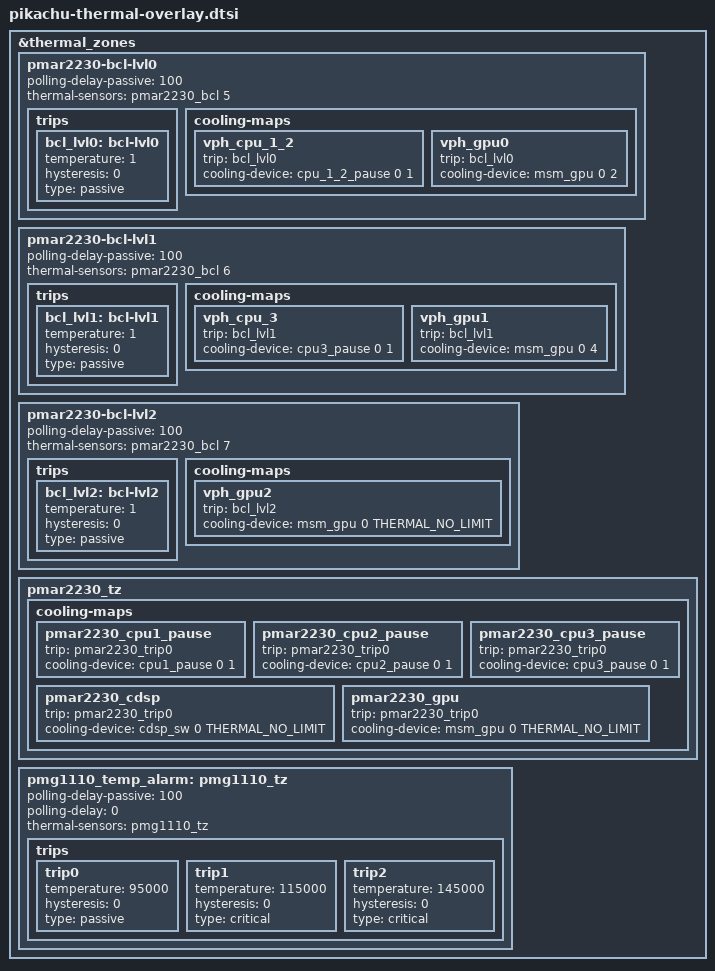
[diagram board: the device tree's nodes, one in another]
// SPDX-License-Identifier: BSD-3-Clause
/*
 * Copyright (c) Qualcomm Technologies, Inc. and/or its subsidiaries.
 */

#include <dt-bindings/thermal/thermal_qti.h>

&thermal_zones {
	pmar2230-bcl-lvl0 {
		polling-delay-passive = <100>;
		thermal-sensors = <&pmar2230_bcl 5>;

		trips {
			bcl_lvl0: bcl-lvl0 {
				temperature = <1>;
				hysteresis = <0>;
				type = "passive";
			};
		};

		cooling-maps {
			vph_cpu_1_2 {
				trip = <&bcl_lvl0>;
				cooling-device = <&cpu_1_2_pause 0 1>;
			};

			vph_gpu0 {
				trip = <&bcl_lvl0>;
				cooling-device = <&msm_gpu 0 2>;
			};
		};
	};

	pmar2230-bcl-lvl1 {
		polling-delay-passive = <100>;
		thermal-sensors = <&pmar2230_bcl 6>;

		trips {
			bcl_lvl1: bcl-lvl1 {
				temperature = <1>;
				hysteresis = <0>;
				type = "passive";
			};
		};

		cooling-maps {
			vph_cpu_3 {
				trip = <&bcl_lvl1>;
				cooling-device = <&cpu3_pause 0 1>;
			};

			vph_gpu1 {
				trip = <&bcl_lvl1>;
				cooling-device = <&msm_gpu 0 4>;
			};
		};
	};

	pmar2230-bcl-lvl2 {
		polling-delay-passive = <100>;
		thermal-sensors = <&pmar2230_bcl 7>;

		trips {
			bcl_lvl2: bcl-lvl2 {
				temperature = <1>;
				hysteresis = <0>;
				type = "passive";
			};
		};

		cooling-maps {
			vph_gpu2 {
				trip = <&bcl_lvl2>;
				cooling-device = <&msm_gpu 0 THERMAL_NO_LIMIT>;
			};
		};
	};

	pmar2230_tz {
		cooling-maps {
			pmar2230_cpu1_pause {
				trip = <&pmar2230_trip0>;
				cooling-device = <&cpu1_pause 0 1>;
			};

			pmar2230_cpu2_pause {
				trip = <&pmar2230_trip0>;
				cooling-device = <&cpu2_pause 0 1>;
			};

			pmar2230_cpu3_pause {
				trip = <&pmar2230_trip0>;
				cooling-device = <&cpu3_pause 0 1>;
			};

			pmar2230_cdsp {
				trip = <&pmar2230_trip0>;
				cooling-device = <&cdsp_sw 0 THERMAL_NO_LIMIT>;
			};

			pmar2230_gpu {
				trip = <&pmar2230_trip0>;
				cooling-device = <&msm_gpu 0 THERMAL_NO_LIMIT>;
			};
		};
	};

	pmg1110_temp_alarm: pmg1110_tz {
		polling-delay-passive = <100>;
		polling-delay = <0>;
		thermal-sensors = <&pmg1110_tz>;

		trips {
			trip0 {
				temperature = <95000>;
				hysteresis = <0>;
				type = "passive";
			};

			trip1 {
				temperature = <115000>;
				hysteresis = <0>;
				type = "critical";
			};

			trip2 {
				temperature = <145000>;
				hysteresis = <0>;
				type = "critical";
			};
		};
	};
};
